# GD32H71x_72x register map
File version: 1.0
CPU: CM7 r1p2, little endian, MPU, FPU, 4 interrupt priority bits
Registers are 32-bit, read-write, reset 0x0 unless marked. A register's access mark holds for its fields unless they carry their own. Offsets are from the block's base; [hi:lo] are bit positions.

## FMC — Flash memory controller
Base 0x52002000
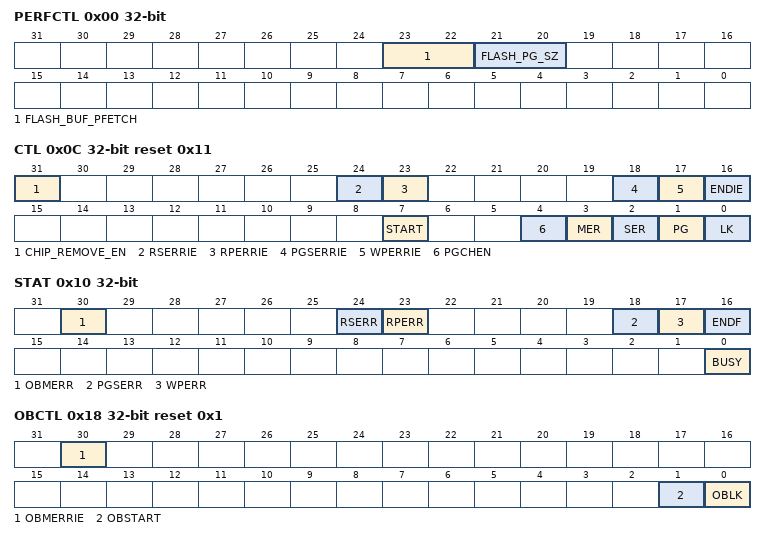
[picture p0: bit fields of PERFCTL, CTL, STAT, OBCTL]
0x00 PERFCTL — Flash performance control register
  [23:22] FLASH_BUF_PFETCH — Flash buffer prefetch control.
  [21:20] FLASH_PG_SZ — Flash program size.
0x04 KEY wo — Unlock key register
  [31:0] KEY — FMC_CTL unlock register
0x08 OBKEY wo — Option byte unlock key register
  [31:0] OBKEY — These bits are only be written by software.
0x0C CTL reset 0x11 — Control register
  [31] CHIP_REMOVE_EN — Protection-removed chip erase enable
  [24] RSERRIE — Read secure error interrupt enable.
  [23] RPERRIE — Read protection error interrupt enable
  [18] PGSERRIE — Program sequence error interrupt enable
  [17] WPERRIE — Erase / program protection error interrupt enable
  [16] ENDIE — End of operation interrupt enable
  [7] START — Send erase command to FMC
  [4] PGCHEN — Check flash programming area enable
  [3] MER — Mass erase command bit
  [2] SER — Sector erase command bit
  [1] PG — Main Flash program command bit
  [0] LK — FMC_CTL lock bit
0x10 STAT access per field — Status register
  [30] OBMERR rw — Option byte modify error flag.
  [24] RSERR rw — Read secure error flag bit.
  [23] RPERR rw — Read protection error flag bit.
  [18] PGSERR rw — Program sequence error flag bit.
  [17] WPERR rw — Erase / program protection error flag bit.
  [16] ENDF rw — End of operation flag bit.
  [0] BUSY ro — The Flash is busy bit
0x14 ADDR — Address register
  [31:0] ADDR — Flash erase command address bits
0x18 OBCTL reset 0x1 — Option byte control register
  [30] OBMERRIE — Option byte modify error interrupt enable.
  [1] OBSTART — Send option byte change command to FMC bit.
  [0] OBLK — FMC_OBCTL lock bit
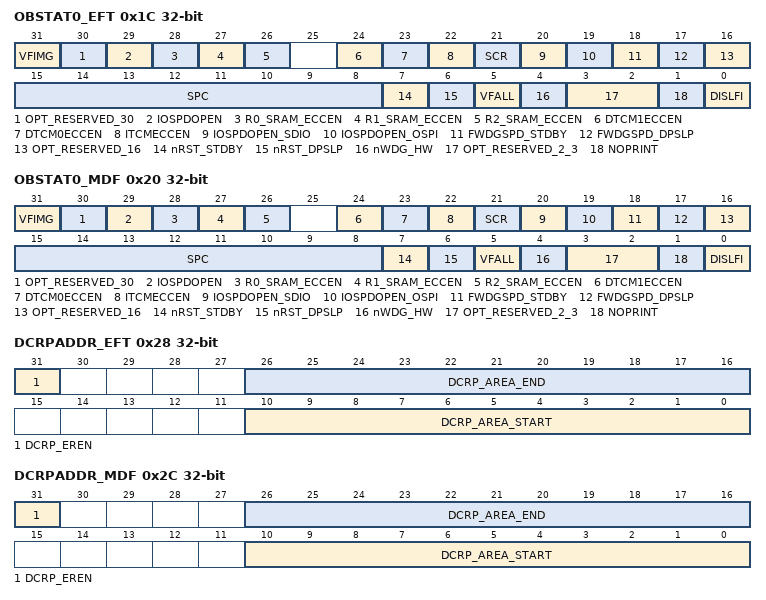
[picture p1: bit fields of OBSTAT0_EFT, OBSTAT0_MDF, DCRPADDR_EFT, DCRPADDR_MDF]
0x1C OBSTAT0_EFT ro — Option byte status register 0
  [31] VFIMG — Firmware image verification enable status bit
  [30] OPT_RESERVED_30 — Option byte reserved bit, available for user use.
  [29] IOSPDOPEN — Allowed enable status bit for I/O speed optimization at low-voltage status bit.
  [28] R0_SRAM_ECCEN — Region 0 SRAM ECC enable status bit
  [27] R1_SRAM_ECCEN — Region 1 SRAM ECC enable status bit
  [26] R2_SRAM_ECCEN — Region 2 SRAM ECC enable status bit
  [24] DTCM1ECCEN — DTCM1 ECC function enable status bit
  [23] DTCM0ECCEN — DTCM0 ECC function enable status bit
  [22] ITCMECCEN — ITCM ECC function enable status bit
  [21] SCR — Secure mode status bit
  [20] IOSPDOPEN_SDIO — Allowed enable status bit for SDIO I/O speed optimization at low-voltage status bit.
  [19] IOSPDOPEN_OSPI — Allowed enable status bit for OSPI I/O speed optimization at low-voltage status bit.
  [18] FWDGSPD_STDBY — FWDGT suspend option in standby mode status bit
  [17] FWDGSPD_DPSLP — FWDGT suspend option in deepsleep mode status bit
  [16] OPT_RESERVED_16 — Option byte reserved bit, available for user use.
  [15:8] SPC — Security protection level option byte status bits
  [7] nRST_STDBY — Option byte standby reset status bit
  [6] nRST_DPSLP — Option byte deepsleep reset status bit
  [5] VFALL — Firmware image (image must contain a certificate) verification enable bit
  [4] nWDG_HW — Watchdog status bit
  [3:2] OPT_RESERVED_2_3 — Option byte reserved bit, available for user use.
  [1] NOPRINT — No information is printed during secure boot status bit
  [0] DISLFI — Licensed firmware install ( LFI ) disable status bit
0x20 OBSTAT0_MDF — Option byte status register 0
  [31] VFIMG — Firmware image verification enable bit
  [30] OPT_RESERVED_30 — Option byte reserved bit, available for user use.
  [29] IOSPDOPEN — Allowed enable bit for I/O speed optimization at low-voltage.
  [28] R0_SRAM_ECCEN — Region 0 SRAM ECC enable bit
  [27] R1_SRAM_ECCEN — Region 1 SRAM ECC enable bit
  [26] R2_SRAM_ECCEN — Region 2 SRAM ECC enable bit
  [24] DTCM1ECCEN — DTCM1 ECC function enable
  [23] DTCM0ECCEN — DTCM0 ECC function enable
  [22] ITCMECCEN — ITCM ECC function enable
  [21] SCR — Secure mode
  [20] IOSPDOPEN_SDIO — Allowed enable bit for SDIO I/O speed optimization at low-voltage.
  [19] IOSPDOPEN_OSPI — Allowed enable bit for OSPI I/O speed optimization at low-voltage.
  [18] FWDGSPD_STDBY — FWDGT suspend option in standby mode
  [17] FWDGSPD_DPSLP — FWDGT suspend option in deepsleep mode
  [16] OPT_RESERVED_16 — Option byte reserved bit, available for user use.
  [15:8] SPC — Security protection level option byte
  [7] nRST_STDBY — Option byte standby reset
  [6] nRST_DPSLP — Option byte deepsleep reset
  [5] VFALL — Firmware image (image must contain a certificate) verification enable bit
  [4] nWDG_HW — Watchdog enable bit
  [3:2] OPT_RESERVED_2_3 — Option byte reserved bit, available for user use.
  [1] NOPRINT — No information is printed during secure boot
  [0] DISLFI — Licensed firmware install ( LFI ) disable
0x28 DCRPADDR_EFT ro — DCRP address register
  [31] DCRP_EREN — DCRP area erase enable status bit.
  [26:16] DCRP_AREA_END — DCRP area end address status bits
  [10:0] DCRP_AREA_START — DCRP area start address status bits
0x2C DCRPADDR_MDF — DCRP address register
  [31] DCRP_EREN — DCRP area erase enable configuration bit.
  [26:16] DCRP_AREA_END — DCRP area end address configuration bits
  [10:0] DCRP_AREA_START — DCRP area start address configuration bits
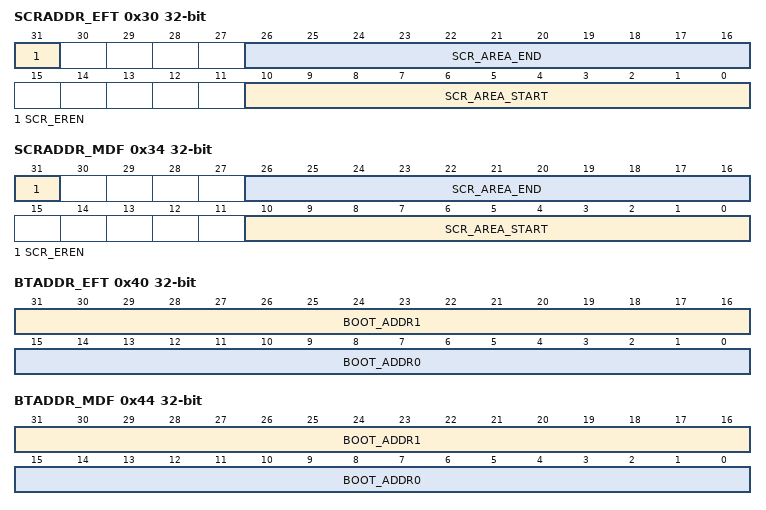
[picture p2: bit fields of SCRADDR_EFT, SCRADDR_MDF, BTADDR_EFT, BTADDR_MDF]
0x30 SCRADDR_EFT ro — Secure address register
  [31] SCR_EREN — Secure user area erase enable option status bit.
  [26:16] SCR_AREA_END — Secure user area end address status bits
  [10:0] SCR_AREA_START — Secure user area start address status bits
0x34 SCRADDR_MDF access per field — Secure address register
  [31] SCR_EREN rw — Secure user area erase enable option configuration bit.
  [26:16] SCR_AREA_END ro — Secure user area end address configuration bits
  [10:0] SCR_AREA_START ro — Secure user area start address configuration bits
0x38 WP_EFT ro — Erase/program protection register
  [29:0] WP — Sector n write protection option status bit
0x3C WP_MDF — Erase/program protection register
  [29:0] WP — Sector n write protection option bit
0x40 BTADDR_EFT ro — Boot address register
  [31:16] BOOT_ADDR1 — Boot address 1 status bits
  [15:0] BOOT_ADDR0 — Boot address 0 status bits
0x44 BTADDR_MDF — Boot address register
  [31:16] BOOT_ADDR1 — Boot address 1 configuration bits.
  [15:0] BOOT_ADDR0 — Boot address 0 configuration bits.
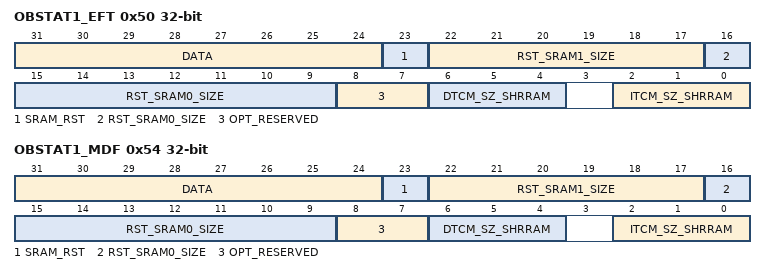
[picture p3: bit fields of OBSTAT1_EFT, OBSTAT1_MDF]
0x50 OBSTAT1_EFT access per field — Option byte status register 1
  [31:24] DATA ro — User defined option byte data status value status bits
  [23] SRAM_RST ro — Initial AXI SRAM0/1 after power reset status bit
  [22:17] RST_SRAM1_SIZE ro — Size of the initialized AXI SRAM1 region after power reset status bits.
  [16:9] RST_SRAM0_SIZE rw — Size of the initialized AXI SRAM0 region after power reset status bits.
  [8:7] OPT_RESERVED ro — Option byte reserved bit 1~0, available for user use.
  [6:4] DTCM_SZ_SHRRAM ro — DTCM size of shared RAM status bits.
  [2:0] ITCM_SZ_SHRRAM ro — ITCM size of shared RAM status bits.
0x54 OBSTAT1_MDF — Option byte status register 1
  [31:24] DATA — User defined option byte data status value
  [23] SRAM_RST — 1: Initial AXI SRAM0/1 after power reset
  [22:17] RST_SRAM1_SIZE — Size of the initialized AXI SRAM1 after power reset.
  [16:9] RST_SRAM0_SIZE — Size of the initialized AXI SRAM0 after power reset.
  [8:7] OPT_RESERVED — Option byte reserved bit 1~0, available for user use.
  [6:4] DTCM_SZ_SHRRAM — DTCM size of shared RAM
  [2:0] ITCM_SZ_SHRRAM — ITCM size of shared RAM
0x100 PID0 ro — Product ID register 0
  [31:0] PID — Product reserved ID code register x
0x104 PID1 ro — Product ID register 1
  [31:0] PID — Product reserved ID code register x
